# STM32F031C4T6 register map
File version: 1.0
Registers are 32-bit, access not given, reset 0x0 unless marked. A register's access mark holds for its fields unless they carry their own. Offsets are from the block's base; [hi:lo] are bit positions; {n}, {i} and the like mark numbered series; 'fields as' and 'values as' point back to an identical list.

## DMA
Base 0x40020000
Same registers: DMA2 0x40020400
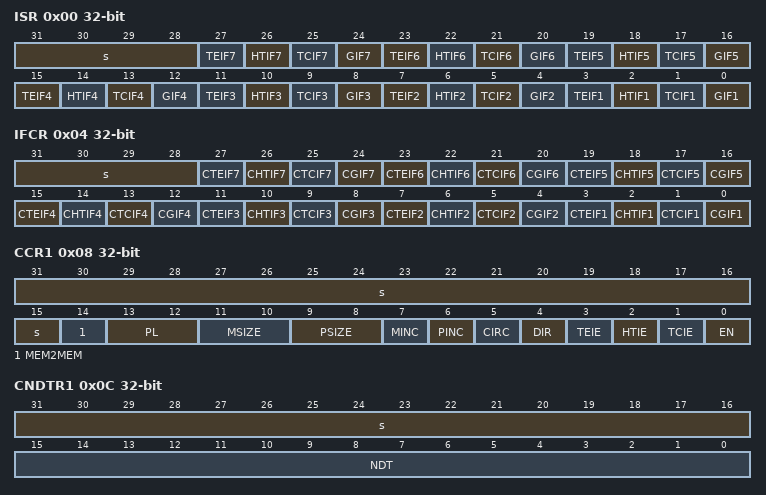
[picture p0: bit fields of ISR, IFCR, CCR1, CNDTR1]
0x00 ISR
  [31:28] s, [4n-1] TEIF{n} (n=1..7), [4n-2] HTIF{n} (n=1..7), [4n-3] TCIF{n} (n=1..7), [4n-4] GIF{n} (n=1..7)
0x04 IFCR
  [31:28] s, [4n-1] CTEIF{n} (n=1..7), [4n-2] CHTIF{n} (n=1..7), [4n-3] CTCIF{n} (n=1..7), [4n-4] CGIF{n} (n=1..7)
0x08 CCR1
  [31:15] s, [14] MEM2MEM, [13:12] PL, [11:10] MSIZE, [9:8] PSIZE, [7] MINC, [6] PINC, [5] CIRC, [4] DIR, [3] TEIE, [2] HTIE, [1] TCIE, [0] EN
0x0C CNDTR1
  [31:16] s, [15:0] NDT
0x10 CPAR1
  [31:0] PA
{0x0+0x14*i} CMAR{i} (i=1..5)
  [31:0] MA
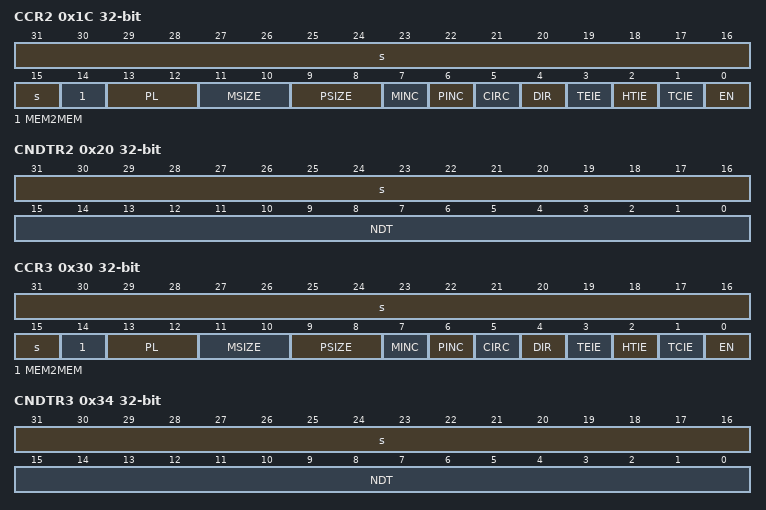
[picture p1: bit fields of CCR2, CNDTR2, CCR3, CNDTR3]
0x1C CCR2
  fields as CCR1
0x20 CNDTR2
  [31:16] s, [15:0] NDT
0x24 CPAR2
  [31:0] PA
0x30 CCR3
  fields as CCR1
0x34 CNDTR3
  [31:16] s, [15:0] NDT
0x38 CPAR3
  [31:0] PA
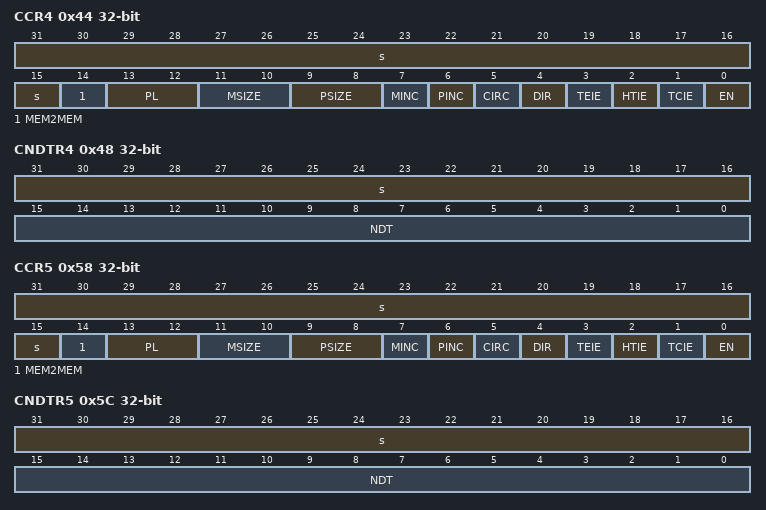
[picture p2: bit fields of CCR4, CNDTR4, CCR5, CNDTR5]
0x44 CCR4
  fields as CCR1
0x48 CNDTR4
  [31:16] s, [15:0] NDT
0x4C CPAR4
  [31:0] PA
0x58 CCR5
  fields as CCR1
0x5C CNDTR5
  [31:16] s, [15:0] NDT
0x60 CPAR5
  [31:0] PA

## RCC
Base 0x40021000
0x00 CR
  [25] PLLRDY, [24] PLLON, [19] CSSON, [18] HSEBYP, [17] HSERDY, [16] HSEON, [15:8] HSICAL, [7:3] HSITRIM, [31:2] s, [1] HSIRDY, [0] HSION
0x04 CFGR
  [31] PLLNODIV, [30:28] MCOPRE, [27:24] MCO, [21:18] PLLMUL, [17] PLLXTPRE, [16:15] PLLSRC, [14] ADCPRE, [23:11] s, [10:8] PPRE, [7:4] HPRE, [3:2] SWS, [1:0] SW
0x08 CIR
  [23] CSSC, [22] HSI48RDYC, [21] HSI14RDYC, [20] PLLRDYC, [19] HSERDYC, [18] HSIRDYC, [17] LSERDYC, [16] LSIRDYC, [31:15] s, [14] HSI48RDYIE, [13] HSI14RDYIE, [12] PLLRDYIE, [11] HSERDYIE, [10] HSIRDYIE, [9] LSERDYIE, [8] LSIRDYIE, [7] CSSF, [6] HSI48RDYF, [5] HSI14RDYF, [4] PLLRDYF, [3] HSERDYF, [2] HSIRDYF, [1] LSERDYF, [0] LSIRDYF
0x0C APB2RSTR
  [22] DBGMCURST, [18] TIM17RST, [17] TIM16RST, [16] TIM15RST, [14] USART1RST, [12] SPI1RST, [11] TIM1RST, [9] ADCRST, [7] USART8RST, [6] USART7RST, [5] USART6RST, [31:1] s, [0] SYSCFGRST
0x10 APB1RSTR
  [30] CECRST, [29] DACRST, [28] PWRRST, [27] CRSRST, [25] CANRST, [23] USBRST, [22] I2C2RST, [21] I2C1RST, [n+15] USART{n}RST (n=2..5), [14] SPI2RST, [11] WWDGRST, [8] TIM14RST, [5] TM7RST, [4] TM6RST, [31:2] s, [1] TIM3RST, [0] TIM2RST
0x14 AHBENR
  [24] TSCEN, [22] IOPFEN, [21] IOPEEN, [20] USART4RST, [19] IOPCEN, [18] IOPBEN, [17] IOPAEN, [6] CRCEN, [4] FLITFEN, [31:3] s, [2] SRAMEN, [1] DAM2EN, [0] DMAEN
0x18 APB2ENR
  [22] DBGMCUEN, [18] TIM17EN, [17] TIM16EN, [16] TIM15EN, [14] USART1EN, [12] SPI1EN, [11] TIM1EN, [9] ADCEN, [7] USART8EN, [6] USART7EN, [5] USART6EN, [31:1] s, [0] SYSCFGCOMPEN
0x1C APB1ENR
  [30] CECEN, [29] DACEN, [28] PWREN, [27] CRSEN, [25] CANEN, [23] USBEN, [22] I2C2EN, [21] I2C1EN, [n+15] USART{n}EN (n=2..5), [14] SPI2EN, [11] WWDGEN, [8] TIM14EN, [5] TIM7EN, [4] TIM6EN, [31:2] s, [1] TIM3EN, [0] TIM2EN
0x20 BDCR
  [16] BDRST, [15] RTCEN, [9:8] RTCSEL, [31:5] s, [4:3] LSEDRV, [2] LSEBYP, [1] LSERDY, [0] LSEON
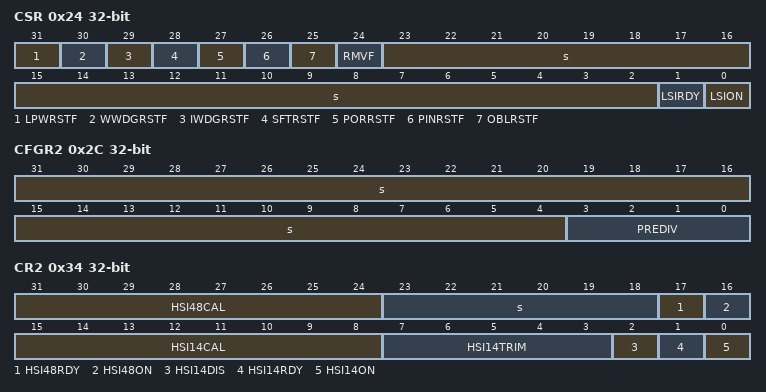
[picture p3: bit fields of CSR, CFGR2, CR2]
0x24 CSR
  [31] LPWRSTF, [30] WWDGRSTF, [29] IWDGRSTF, [28] SFTRSTF, [27] PORRSTF, [26] PINRSTF, [25] OBLRSTF, [24] RMVF, [23:2] s, [1] LSIRDY, [0] LSION
0x28 AHBRSTR
  [24] TSCRST, [22] IOPFRST, [21] IOPERST, [20] IOPDRST, [19] IOPCRST, [18] IOPBRST, [17] IOPARST, [31:0] s
0x2C CFGR2
  [31:4] s, [3:0] PREDIV
0x30 CFGR3
  [19:18] USART3SW, [17:16] USART2SW, [8] ADCSW, [7] USBSW, [6] CECSW, [4] I2C1SW, [31:2] s, [1:0] USART1SW
0x34 CR2
  [31:24] HSI48CAL, [23:18] s, [17] HSI48RDY, [16] HSI48ON, [15:8] HSI14CAL, [7:3] HSI14TRIM, [2] HSI14DIS, [1] HSI14RDY, [0] HSI14ON

## FLASH
Base 0x40022000
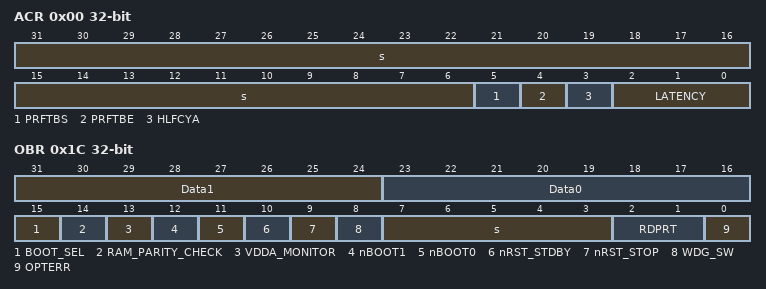
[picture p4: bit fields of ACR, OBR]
0x00 ACR
  [31:6] s, [5] PRFTBS, [4] PRFTBE, [3] HLFCYA, [2:0] LATENCY
0x04 KEYR
  [31:0] FKEY
0x08 OPTKEYR
  [31:0] OPTKEY
0x0C SR
  [5] EOP, [4] WRPRTERR, [31:3] s, [2] PGERR, [1] ERLYBSY, [0] BSY
0x10 CR
  [13] OBL_LAUNCH, [12] EOPIE, [10] ERRIE, [9] OPTWRE, [7] LOCK, [6] STRT, [5] OPTER, [4] OPTPG, [31:3] s, [2] MER, [1] PER, [0] PG
0x14 AR
  [31:0] FAR
0x1C OBR
  [31:24] Data1, [23:16] Data0, [15] BOOT_SEL, [14] RAM_PARITY_CHECK, [13] VDDA_MONITOR, [12] nBOOT1, [11] nBOOT0, [10] nRST_STDBY, [9] nRST_STOP, [8] WDG_SW, [7:3] s, [2:1] RDPRT, [0] OPTERR
0x20 WRPR
  [31:0] WRP

## CRC
Base 0x40023000
0x00 DR
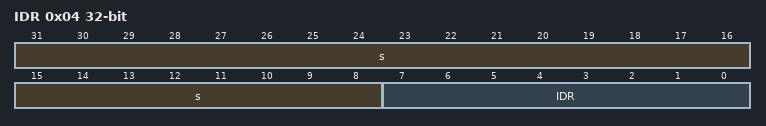
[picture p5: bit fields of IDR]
0x04 IDR
  [31:8] s, [7:0] IDR
0x08 CR
  [7] REV_OUT, [6:5] REV_IN, [4:3] POLYSIZE, [31:1] s, [0] RESET
0x10 INIT
  [31:0] CRC_INIT
0x14 POL

## TSC
Base 0x40024000
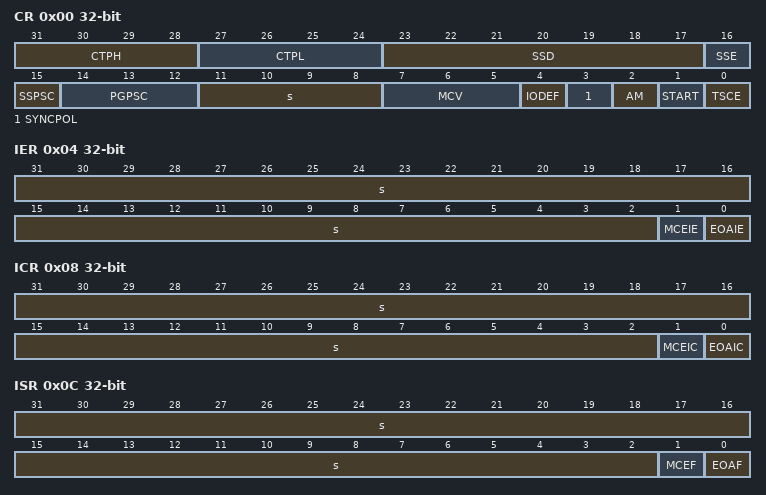
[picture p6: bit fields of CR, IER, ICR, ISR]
0x00 CR
  [31:28] CTPH, [27:24] CTPL, [23:17] SSD, [16] SSE, [15] SSPSC, [14:12] PGPSC, [11:8] s, [7:5] MCV, [4] IODEF, [3] SYNCPOL, [2] AM, [1] START, [0] TSCE
0x04 IER
  [31:2] s, [1] MCEIE, [0] EOAIE
0x08 ICR
  [31:2] s, [1] MCEIC, [0] EOAIC
0x0C ISR
  [31:2] s, [1] MCEF, [0] EOAF
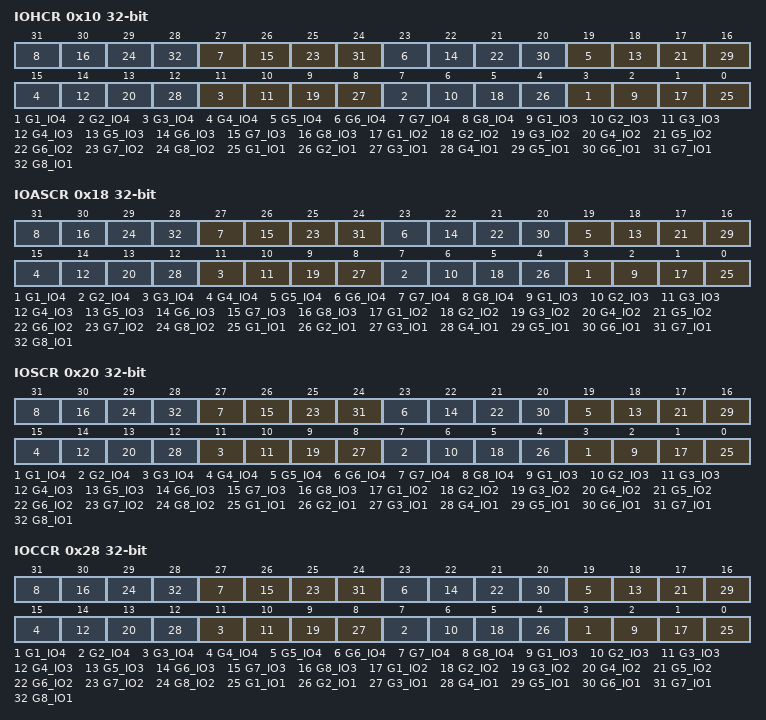
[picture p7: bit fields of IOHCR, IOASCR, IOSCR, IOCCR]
0x10 IOHCR
  [4n-1] G{n}_IO4 (n=1..8), [4n-2] G{n}_IO3 (n=1..8), [4n-3] G{n}_IO2 (n=1..8), [4n-4] G{n}_IO1 (n=1..8)
0x18 IOASCR
  fields as IOHCR
0x20 IOSCR
  fields as IOHCR
0x28 IOCCR
  fields as IOHCR
0x30 IOGCSR
  [n+15] G{n}S (n=1..8), [31:8] s, [n-1] G{n}E (n=1..8)
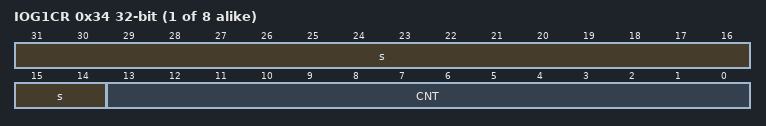
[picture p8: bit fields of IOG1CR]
{0x30+4i} IOG{i}CR (i=1..8)
  [31:14] s, [13:0] CNT

## GPIOA
Base 0x48000000
Same registers: GPIOB 0x48000400, GPIOC 0x48000800, GPIOD 0x48000C00, GPIOE 0x48001000, GPIOF 0x48001400
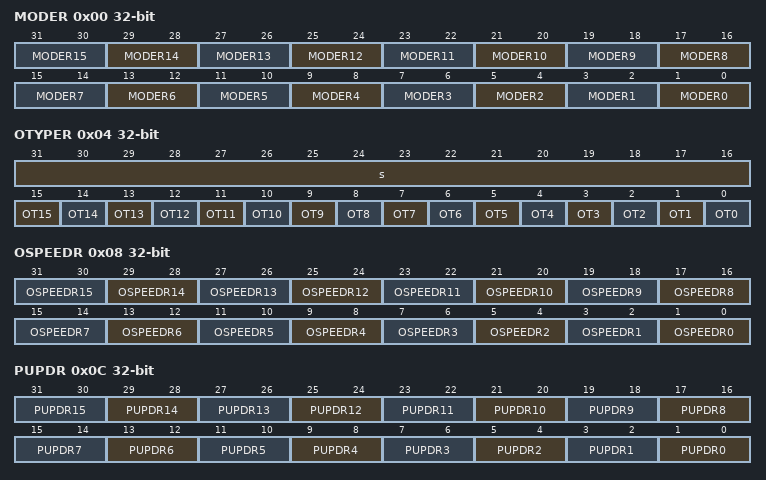
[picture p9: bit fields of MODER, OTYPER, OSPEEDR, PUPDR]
0x00 MODER
  [2n+1:2n] MODER{n} (n=0..15)
0x04 OTYPER
  [31:16] s, [n] OT{n} (n=0..15)
0x08 OSPEEDR
  [2n+1:2n] OSPEEDR{n} (n=0..15)
0x0C PUPDR
  [2n+1:2n] PUPDR{n} (n=0..15)
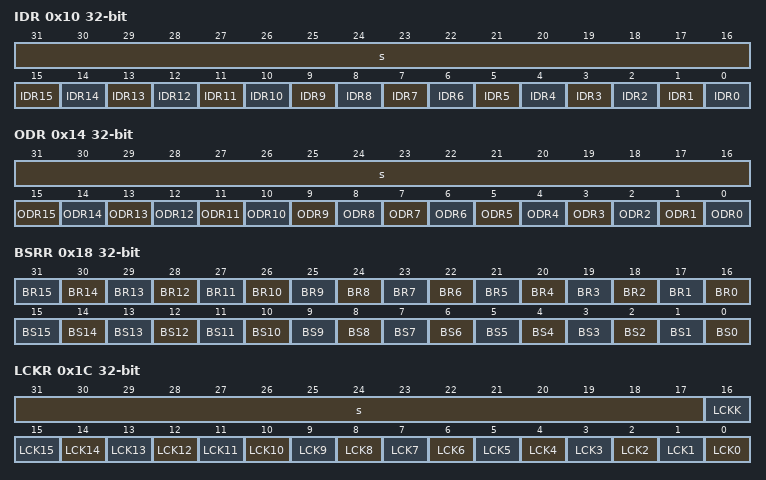
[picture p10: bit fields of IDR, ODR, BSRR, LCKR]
0x10 IDR
  [31:16] s, [n] IDR{n} (n=0..15)
0x14 ODR
  [31:16] s, [n] ODR{n} (n=0..15)
0x18 BSRR
  [n+16] BR{n} (n=0..15), [n] BS{n} (n=0..15)
0x1C LCKR
  [31:17] s, [16] LCKK, [n] LCK{n} (n=0..15)
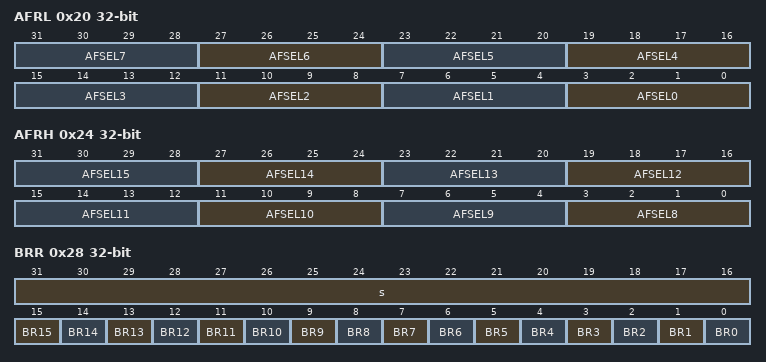
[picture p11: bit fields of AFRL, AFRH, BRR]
0x20 AFRL
  [4n+3:4n] AFSEL{n} (n=0..7)
0x24 AFRH
  [4n-29:4n-32] AFSEL{n} (n=8..15)
0x28 BRR
  [31:16] s, [n] BR{n} (n=0..15)
